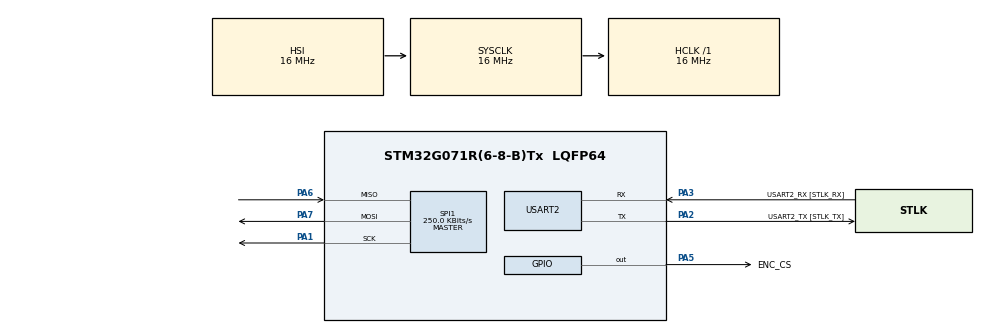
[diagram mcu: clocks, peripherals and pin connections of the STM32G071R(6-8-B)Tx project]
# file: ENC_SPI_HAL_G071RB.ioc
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Mcu.Family=STM32G0
Mcu.Name=STM32G071R(6-8-B)Tx
Mcu.Package=LQFP64
PA1.Mode=Full_Duplex_Master
PA1.Signal=SPI1_SCK
PA13.GPIO_Label=TMS
PA13.Mode=Serial_Wire
PA13.Signal=SYS_SWDIO
PA14-BOOT0.GPIO_Label=TCK
PA14-BOOT0.Mode=Serial_Wire
PA14-BOOT0.Signal=SYS_SWCLK
PA2.GPIO_Label=USART2_TX [STLK_TX]
PA2.GPIO_PuPd=GPIO_PULLUP
PA2.Mode=Asynchronous
PA2.Signal=USART2_TX
PA3.GPIO_Label=USART2_RX [STLK_RX]
PA3.GPIO_PuPd=GPIO_PULLUP
PA3.Mode=Asynchronous
PA3.Signal=USART2_RX
PA5.GPIO_Label=ENC_CS
PA5.GPIO_Speed=GPIO_SPEED_FREQ_HIGH
PA5.Signal=GPIO_Output
PA6.Mode=Full_Duplex_Master
PA6.Signal=SPI1_MISO
PA7.Mode=Full_Duplex_Master
PA7.Signal=SPI1_MOSI
PC13.Mode=SYS_WakeUp1
PC13.Signal=SYS_WKUP2
PC14-OSC32_IN\ (PC14).Mode=LSE-External-Oscillator
PC14-OSC32_IN\ (PC14).Signal=RCC_OSC32_IN
PC15-OSC32_OUT\ (PC15).Mode=LSE-External-Oscillator
PC15-OSC32_OUT\ (PC15).Signal=RCC_OSC32_OUT
PF0-OSC_IN\ (PF0).GPIO_Label=MCO
PF0-OSC_IN\ (PF0).Mode=HSE-External-Clock-Source
PF0-OSC_IN\ (PF0).Signal=RCC_OSC_IN
ProjectManager.HeapSize=0x200
ProjectManager.StackSize=0x400
ProjectManager.TargetToolchain=STM32CubeIDE
RCC.AHBFreq_Value=16000000
RCC.CortexFreq_Value=16000000
RCC.EXTERNAL_CLOCK_VALUE=12288000
RCC.HCLKFreq_Value=16000000
RCC.HSE_VALUE=8000000
RCC.HSI_VALUE=16000000
RCC.SYSCLKFreq_VALUE=16000000
RCC.VCOOutputFreq_Value=128000000
SPI1.BaudRatePrescaler=SPI_BAUDRATEPRESCALER_64
SPI1.CalculateBaudRate=250.0 KBits/s
SPI1.DataSize=SPI_DATASIZE_8BIT
SPI1.Direction=SPI_DIRECTION_2LINES
SPI1.Mode=SPI_MODE_MASTER
SPI1.VirtualType=VM_MASTER
USART2.VirtualMode-Asynchronous=VM_ASYNC
board=NUCLEO-G071RB

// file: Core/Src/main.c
/* USER CODE BEGIN Header */
/**
  * FINAL INTEGRATION: STM32 + ENC28J60 + LwIP
  * CS Pin: PA5 (Green LED) - Hardwired Override
  */
/* USER CODE END Header */

#include "main.h"
#include <stdio.h>
#include <string.h>

/* LwIP Includes */
#include "lwip/init.h"
#include "lwip/netif.h"
#include "lwip/timeouts.h"
#include "netif/ethernet.h"
#include "ethernetif.h"
#include "enc28j60.h"
#include "tcp_echo.h"
#include "http_server.h"
#if LWIP_DHCP
#include "lwip/dhcp.h"  // <-- Needed if DHCP is enabled
#include "thingspeak.h"
#endif

/* Global Variables */
struct netif gnetif;

SPI_HandleTypeDef hspi1;
UART_HandleTypeDef huart2;
ENC_HandleTypeDef henc;

void SystemClock_Config(void);
static void MX_GPIO_Init(void);
static void MX_SPI1_Init(void);
static void MX_USART2_UART_Init(void);

int main(void)
{
  HAL_Init();
  SystemClock_Config();
  MX_GPIO_Init();
  MX_SPI1_Init();
  MX_USART2_UART_Init();

  /* USER CODE BEGIN 2 */

  // --- 1. HARDWARE FIX: Force PA5 (LED) to be our Chip Select ---
  GPIO_InitTypeDef GPIO_InitStruct = {0};
  __HAL_RCC_GPIOA_CLK_ENABLE();
  HAL_GPIO_WritePin(GPIOA, GPIO_PIN_5, GPIO_PIN_SET); // Deselect
  GPIO_InitStruct.Pin = GPIO_PIN_5;
  GPIO_InitStruct.Mode = GPIO_MODE_OUTPUT_PP;
  GPIO_InitStruct.Pull = GPIO_NOPULL;
  GPIO_InitStruct.Speed = GPIO_SPEED_FREQ_VERY_HIGH;
  HAL_GPIO_Init(GPIOA, &GPIO_InitStruct);

  // 2. UART Debug Message
  char msg[100];
  sprintf(msg, "\r\n--- STM32 + LwIP + ENC28J60 START ---\r\n");
  HAL_UART_Transmit(&huart2, (uint8_t*)msg, strlen(msg), 100);
  HAL_Delay(100);

  // 3. Configure Driver
  henc.Init.MACAddr[0] = 0x54;
  henc.Init.MACAddr[1] = 0x55;
  henc.Init.MACAddr[2] = 0x58;
  henc.Init.MACAddr[3] = 0x10;
  henc.Init.MACAddr[4] = 0x00;
  henc.Init.MACAddr[5] = 0x24;

  henc.Init.DuplexMode = ETH_MODE_HALFDUPLEX; // Forced Half-Duplex
  henc.Init.ChecksumMode = ETH_CHECKSUM_BY_HARDWARE;
  henc.Init.InterruptEnableBits = 0;

  // 4. Start Driver
  sprintf(msg, "Initializing Hardware Driver...\r\n");
  HAL_UART_Transmit(&huart2, (uint8_t*)msg, strlen(msg), 100);

  if (enc_start(&henc)) {
      sprintf(msg, "SUCCESS! ENC28J60 found and initialized.\r\n");
      HAL_UART_Transmit(&huart2, (uint8_t*)msg, strlen(msg), 100);
      for(int i=0; i<6; i++) { HAL_GPIO_TogglePin(GPIOA, GPIO_PIN_5); HAL_Delay(50); }
  } else {
      sprintf(msg, "FAILURE! Could not detect ENC28J60.\r\n");
      HAL_UART_Transmit(&huart2, (uint8_t*)msg, strlen(msg), 100);
      Error_Handler();
  }

  HAL_UART_Transmit(&huart2, (uint8_t*)"Forcing MAC update...\r\n", 23, 100);
    enc_force_mac_hardware(&henc);
    HAL_UART_Transmit(&huart2, (uint8_t*)"MAC Updated.\r\n", 14, 100);

  // 5. LwIP Init
  lwip_init();
#if !USE_DHCP
  app_echoserver_init();  // Starts the Echo Server (Port 7)
#endif
  http_server_init();     // Starts your HTTP Server (Port 80) <--- Add this

  // 6. IP Settings
  ip4_addr_t ipaddr, netmask, gw;

#if USE_DHCP
  // For DHCP, LwIP requires starting with 0.0.0.0
  IP4_ADDR(&ipaddr, 0, 0, 0, 0);
  IP4_ADDR(&netmask, 0, 0, 0, 0);
  IP4_ADDR(&gw, 0, 0, 0, 0);
#else
  IP4_ADDR(&ipaddr, 192, 168, 0, 200);
  IP4_ADDR(&netmask, 255, 255, 255, 0);
  IP4_ADDR(&gw, 192, 168, 0, 1);
#endif

  // 7. Add Interface
  netif_add(&gnetif, &ipaddr, &netmask, &gw, NULL, &ethernetif_init, &ethernet_input);
  netif_set_default(&gnetif);

  if (netif_is_link_up(&gnetif)) {
      netif_set_up(&gnetif);
#if USE_DHCP
      HAL_UART_Transmit(&huart2, (uint8_t*)"Link UP! Waiting for DHCP...\r\n", 30, 100);
#else
      sprintf(msg, "LwIP UP! IP: 192.168.0.200\r\n");
      HAL_UART_Transmit(&huart2, (uint8_t*)msg, strlen(msg), 100);
#endif
  } else {
      netif_set_up(&gnetif);
#if USE_DHCP
      HAL_UART_Transmit(&huart2, (uint8_t*)"Link DOWN? Forcing UP! Waiting for DHCP...\r\n", 44, 100);
#else
      sprintf(msg, "LwIP UP (Forced). IP: 192.168.0.200\r\n");
      HAL_UART_Transmit(&huart2, (uint8_t*)msg, strlen(msg), 100);
#endif
  }

#if USE_DHCP
  dhcp_start(&gnetif); // Start the DHCP client process
  thingspeak_init(); // ThingSpeak Init
#endif

  /* USER CODE END 2 */

  /* Infinite loop */
#if TEST_MODE_LED
  uint32_t last_arp_time = 0;
#endif

#if USE_DHCP
  uint8_t dhcp_ip_printed = 0; // Flag to only print IP once
#endif

 while (1)
  {
    ethernetif_input(&gnetif);
    sys_check_timeouts();

#if USE_DHCP
  // Check if DHCP has assigned an IP address yet
  if (!dhcp_ip_printed)
   {
	  uint32_t my_ip = netif_ip4_addr(&gnetif)->addr;
	  if (my_ip != 0) { // 0 means no IP yet. Anything else means success!
	  char ip_msg[64];
	  snprintf(ip_msg, sizeof(ip_msg), "\r\n>>> SUCCESS! DHCP IP is: %lu.%lu.%lu.%lu <<<\r\n",
	  (my_ip & 0xff), ((my_ip >> 8) & 0xff), ((my_ip >> 16) & 0xff), (my_ip >> 24));
	  HAL_UART_Transmit(&huart2, (uint8_t*)ip_msg, strlen(ip_msg), 100);
	  dhcp_ip_printed = 1; // Stop checking
   }
  }

  // ThingSpeak Cloud Telemetry (Fires every 20 seconds)
  static uint32_t last_ts_time = 0;

  // ONLY send if we actually have an IP address from DHCP!
  if (dhcp_ip_printed && (HAL_GetTick() - last_ts_time > 20000))
  {
	 last_ts_time = HAL_GetTick();

	 // Create some dummy data to upload
	 static int ts_counter = 0;
	 int uptime_seconds = HAL_GetTick() / 1000;

	 thingspeak_send(uptime_seconds, ts_counter++);
  }
#endif

#if TEST_MODE_LED
 // Safe Test LED (1 Second)
 // In case If system doesnt work simple test to check basic LED Blinky
  if (HAL_GetTick() - last_arp_time > 1000)
  {
	 last_arp_time = HAL_GetTick();
	 HAL_GPIO_TogglePin(LED_BLUE_GPIO_Port, LED_BLUE_Pin);
  }
#endif
  }
}

void SystemClock_Config(void)
{
  RCC_OscInitTypeDef RCC_OscInitStruct = {0};
  RCC_ClkInitTypeDef RCC_ClkInitStruct = {0};
  HAL_PWREx_ControlVoltageScaling(PWR_REGULATOR_VOLTAGE_SCALE1);
  RCC_OscInitStruct.OscillatorType = RCC_OSCILLATORTYPE_HSI;
  RCC_OscInitStruct.HSIState = RCC_HSI_ON;
  RCC_OscInitStruct.HSIDiv = RCC_HSI_DIV1;
  RCC_OscInitStruct.HSICalibrationValue = RCC_HSICALIBRATION_DEFAULT;
  RCC_OscInitStruct.PLL.PLLState = RCC_PLL_NONE;
  if (HAL_RCC_OscConfig(&RCC_OscInitStruct) != HAL_OK) Error_Handler();
  RCC_ClkInitStruct.ClockType = RCC_CLOCKTYPE_HCLK|RCC_CLOCKTYPE_SYSCLK|RCC_CLOCKTYPE_PCLK1;
  RCC_ClkInitStruct.SYSCLKSource = RCC_SYSCLKSOURCE_HSI;
  RCC_ClkInitStruct.AHBCLKDivider = RCC_SYSCLK_DIV1;
  RCC_ClkInitStruct.APB1CLKDivider = RCC_HCLK_DIV1;
  if (HAL_RCC_ClockConfig(&RCC_ClkInitStruct, FLASH_LATENCY_0) != HAL_OK) Error_Handler();
}

static void MX_SPI1_Init(void)
{
  hspi1.Instance = SPI1;
  hspi1.Init.Mode = SPI_MODE_MASTER;
  hspi1.Init.Direction = SPI_DIRECTION_2LINES;
  hspi1.Init.DataSize = SPI_DATASIZE_8BIT;
  hspi1.Init.CLKPolarity = SPI_POLARITY_LOW;
  hspi1.Init.CLKPhase = SPI_PHASE_1EDGE;
  hspi1.Init.NSS = SPI_NSS_SOFT;
  hspi1.Init.BaudRatePrescaler = SPI_BAUDRATEPRESCALER_16;
  hspi1.Init.FirstBit = SPI_FIRSTBIT_MSB;
  hspi1.Init.TIMode = SPI_TIMODE_DISABLE;
  hspi1.Init.CRCCalculation = SPI_CRCCALCULATION_DISABLE;
  hspi1.Init.NSSPMode = SPI_NSS_PULSE_DISABLE;
  if (HAL_SPI_Init(&hspi1) != HAL_OK) Error_Handler();
}

static void MX_USART2_UART_Init(void)
{
  huart2.Instance = USART2;
  huart2.Init.BaudRate = 115200;
  huart2.Init.WordLength = UART_WORDLENGTH_8B;
  huart2.Init.StopBits = UART_STOPBITS_1;
  huart2.Init.Parity = UART_PARITY_NONE;
  huart2.Init.Mode = UART_MODE_TX_RX;
  huart2.Init.HwFlowCtl = UART_HWCONTROL_NONE;
  huart2.Init.OverSampling = UART_OVERSAMPLING_16;
  HAL_UART_Init(&huart2);
}

static void MX_GPIO_Init(void)
{
  __HAL_RCC_GPIOA_CLK_ENABLE();
  __HAL_RCC_GPIOB_CLK_ENABLE();

  GPIO_InitTypeDef GPIO_InitStruct = {0};

  HAL_GPIO_WritePin(LED_BLUE_GPIO_Port, LED_BLUE_Pin, GPIO_PIN_RESET); // Start OFF

    GPIO_InitStruct.Pin = LED_BLUE_Pin;
    GPIO_InitStruct.Mode = GPIO_MODE_OUTPUT_PP; // Push-Pull Output
    GPIO_InitStruct.Pull = GPIO_NOPULL;
    GPIO_InitStruct.Speed = GPIO_SPEED_FREQ_LOW;
    HAL_GPIO_Init(LED_BLUE_GPIO_Port, &GPIO_InitStruct);
}

void Error_Handler(void)
{
  __disable_irq();
  while (1) {}
}

uint32_t sys_now(void)
{
  return HAL_GetTick();
}
